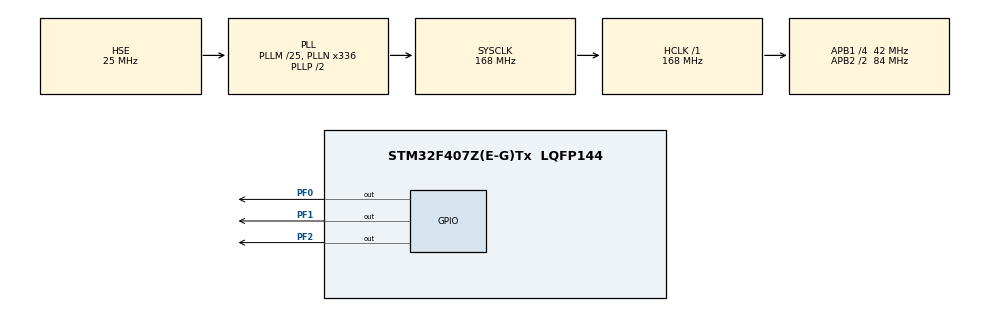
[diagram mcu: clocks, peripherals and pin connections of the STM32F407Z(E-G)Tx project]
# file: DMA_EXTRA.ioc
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Dma.MEMTOMEM.0.Direction=DMA_MEMORY_TO_MEMORY
Dma.MEMTOMEM.0.FIFOMode=DMA_FIFOMODE_ENABLE
Dma.MEMTOMEM.0.FIFOThreshold=DMA_FIFO_THRESHOLD_1QUARTERFULL
Dma.MEMTOMEM.0.Instance=DMA2_Stream0
Dma.MEMTOMEM.0.MemBurst=DMA_MBURST_SINGLE
Dma.MEMTOMEM.0.MemDataAlignment=DMA_MDATAALIGN_WORD
Dma.MEMTOMEM.0.MemInc=DMA_MINC_ENABLE
Dma.MEMTOMEM.0.Mode=DMA_NORMAL
Dma.MEMTOMEM.0.PeriphBurst=DMA_PBURST_SINGLE
Dma.MEMTOMEM.0.PeriphDataAlignment=DMA_PDATAALIGN_BYTE
Dma.MEMTOMEM.0.PeriphInc=DMA_PINC_ENABLE
Dma.MEMTOMEM.0.Priority=DMA_PRIORITY_LOW
Dma.Request0=MEMTOMEM
Mcu.Family=STM32F4
Mcu.Name=STM32F407Z(E-G)Tx
Mcu.Package=LQFP144
NVIC.PriorityGroup=NVIC_PRIORITYGROUP_4
PF0.PinState=GPIO_PIN_SET
PF0.Signal=GPIO_Output
PF1.PinState=GPIO_PIN_SET
PF1.Signal=GPIO_Output
PF2.PinState=GPIO_PIN_SET
PF2.Signal=GPIO_Output
PH0-OSC_IN.Mode=HSE-External-Oscillator
PH0-OSC_IN.Signal=RCC_OSC_IN
PH1-OSC_OUT.Mode=HSE-External-Oscillator
PH1-OSC_OUT.Signal=RCC_OSC_OUT
ProjectManager.HeapSize=0x200
ProjectManager.StackSize=0x400
ProjectManager.TargetToolchain=STM32CubeIDE
RCC.48MHZClocksFreq_Value=84000000
RCC.AHBFreq_Value=168000000
RCC.APB1CLKDivider=RCC_HCLK_DIV4
RCC.APB1Freq_Value=42000000
RCC.APB1TimFreq_Value=84000000
RCC.APB2CLKDivider=RCC_HCLK_DIV2
RCC.APB2Freq_Value=84000000
RCC.APB2TimFreq_Value=168000000
RCC.CortexFreq_Value=168000000
RCC.HCLKFreq_Value=168000000
RCC.HSE_VALUE=25000000
RCC.HSI_VALUE=16000000
RCC.LSE_VALUE=32768
RCC.PLLM=25
RCC.PLLN=336
RCC.PLLSourceVirtual=RCC_PLLSOURCE_HSE
RCC.SYSCLKFreq_VALUE=168000000
RCC.SYSCLKSource=RCC_SYSCLKSOURCE_PLLCLK
RCC.VCOOutputFreq_Value=336000000
board=custom

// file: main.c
/* USER CODE BEGIN Header */
/**
  ******************************************************************************
  * @file           : main.c
  * @brief          : Main program body
  ******************************************************************************
  * @attention
  *
  * Copyright (c) 2022 STMicroelectronics.
  * All rights reserved.
  *
  * This software is licensed under terms that can be found in the LICENSE file
  * in the root directory of this software component.
  * If no LICENSE file comes with this software, it is provided AS-IS.
  *
  ******************************************************************************
  */
/* USER CODE END Header */
#include "main.h"
#include "dma.h"
#include "gpio.h"

/* USER CODE BEGIN PTD */
typedef enum
{
	FAILED = 0,
	PASSED = !FAILED
}TestStatus;
/* USER CODE END PTD */

/* USER CODE BEGIN PM */
static const uint8_t SRC_ConstBuffer[32]={
		0x00,0x01,0x02,0x03,
		0x04,0x05,0x06,0x07,
		0x00,0x01,0x02,0x03,
		0x00,0x01,0x02,0x03,
		0x00,0x01,0x02,0x03,
		0x00,0x01,0x02,0x03,
		0x00,0x01,0x02,0x03,
		0x00,0x01,0x02,0x03
};
/* USER CODE END PM */

void SystemClock_Config(void);

int main(void)
{
  /* USER CODE BEGIN 1 */
	uint32_t Dst_ConstBuffer[8]={0};
	int har_status;
	TestStatus TransferStates;
  /* USER CODE END 1 */

  /* MCU Configuration--------------------------------------------------------*/

  /* Reset of all peripherals, Initializes the Flash interface and the Systick. */
  HAL_Init();

  /* Configure the system clock */
  SystemClock_Config();

  /* Initialize all configured peripherals */
  MX_GPIO_Init();
  MX_DMA_Init();
  /* USER CODE BEGIN 2 */
  har_status = HAL_DMA_Start(&hdma_memtomem_dma2_stream0,
 		  (uint32_t)&SRC_ConstBuffer, (uint32_t)&Dst_ConstBuffer, 32);

  /* USER CODE END 2 */

  /* Infinite loop */
  while (1)
  {

  }
}

void SystemClock_Config(void)
{
  RCC_OscInitTypeDef RCC_OscInitStruct = {0};
  RCC_ClkInitTypeDef RCC_ClkInitStruct = {0};

  /** Configure the main internal regulator output voltage
  */
  __HAL_RCC_PWR_CLK_ENABLE();
  __HAL_PWR_VOLTAGESCALING_CONFIG(PWR_REGULATOR_VOLTAGE_SCALE1);

  /** Initializes the RCC Oscillators according to the specified parameters
  * in the RCC_OscInitTypeDef structure.
  */
  RCC_OscInitStruct.OscillatorType = RCC_OSCILLATORTYPE_HSE;
  RCC_OscInitStruct.HSEState = RCC_HSE_ON;
  RCC_OscInitStruct.PLL.PLLState = RCC_PLL_ON;
  RCC_OscInitStruct.PLL.PLLSource = RCC_PLLSOURCE_HSE;
  RCC_OscInitStruct.PLL.PLLM = 25;
  RCC_OscInitStruct.PLL.PLLN = 336;
  RCC_OscInitStruct.PLL.PLLP = RCC_PLLP_DIV2;
  RCC_OscInitStruct.PLL.PLLQ = 4;
  if (HAL_RCC_OscConfig(&RCC_OscInitStruct) != HAL_OK)
  {
    Error_Handler();
  }

  /** Initializes the CPU, AHB and APB buses clocks
  */
  RCC_ClkInitStruct.ClockType = RCC_CLOCKTYPE_HCLK|RCC_CLOCKTYPE_SYSCLK
                              |RCC_CLOCKTYPE_PCLK1|RCC_CLOCKTYPE_PCLK2;
  RCC_ClkInitStruct.SYSCLKSource = RCC_SYSCLKSOURCE_PLLCLK;
  RCC_ClkInitStruct.AHBCLKDivider = RCC_SYSCLK_DIV1;
  RCC_ClkInitStruct.APB1CLKDivider = RCC_HCLK_DIV4;
  RCC_ClkInitStruct.APB2CLKDivider = RCC_HCLK_DIV2;

  if (HAL_RCC_ClockConfig(&RCC_ClkInitStruct, FLASH_LATENCY_5) != HAL_OK)
  {
    Error_Handler();
  }
}

void Error_Handler(void)
{
  __disable_irq();
  while (1)
  {
  }
}
